AUTOSAR XML (schema 00048)
package /ComponentTypes
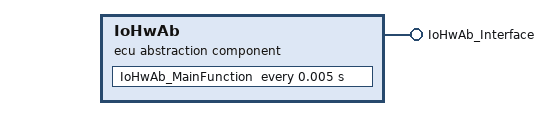
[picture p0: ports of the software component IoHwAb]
  ecu abstraction sw component type IoHwAb
    provide port IoHwAb_Interface: provided-interface=IoHwAb_Interface
      provided-com-specs:
        operation=SetHsLsOutput, queue-length=1
        operation=SetPeriodAndDuty, queue-length=1
        operation=SetDuty, queue-length=1
        operation=SetPin, queue-length=1
        operation=GetPin, queue-length=1
        operation=GetVoltage, queue-length=1
    behavior IoHwAb_InternalBehavior
      exclusive area ExclusiveArea_IoHwAb
      timing event TMT_IoHwAb_MainFunction: start-on-event=IoHwAb_MainFunction, period=0.005
      6 x operation invoked event:
        OIT_IoHwAb_Interface_SetHsLsOutput_IoHwAb_Interface_SetHsLsOutput: start-on-event=IoHwAb_SetHsLsOutput, operation=IoHwAb_Interface.SetHsLsOutput
        OIT_IoHwAb_Interface_SetPeriodAndDuty_IoHwAb_Interface_SetPeriodAndDuty: start-on-event=IoHwAb_SetPeriodAndDuty, operation=IoHwAb_Interface.SetPeriodAndDuty
        OIT_IoHwAb_Interface_SetDuty_IoHwAb_Interface_SetDuty: start-on-event=IoHwAb_SetDuty, operation=IoHwAb_Interface.SetDuty
        OIT_IoHwAb_Interface_SetPin_IoHwAb_Interface_SetPin: start-on-event=IoHwAb_SetPin, operation=IoHwAb_Interface.SetPin
        OIT_IoHwAb_Interface_GetPin_IoHwAb_Interface_GetPin: start-on-event=IoHwAb_GetPin, operation=IoHwAb_Interface.GetPin
        OIT_IoHwAb_Interface_GetVoltage_IoHwAb_Interface_GetVoltage: start-on-event=IoHwAb_GetVoltage, operation=IoHwAb_Interface.GetVoltage
      7 x runnable:
        IoHwAb_MainFunction: can-enter-exclusive-area=ExclusiveArea_IoHwAb
        IoHwAb_SetHsLsOutput
        IoHwAb_SetPeriodAndDuty
        IoHwAb_SetDuty
        IoHwAb_SetPin
        IoHwAb_GetPin
        IoHwAb_GetVoltage
  swc implementation IoHwAb_Implementation: behavior=IoHwAb_InternalBehavior
